VERSION ""

NS_ :

BS_:

BU_:

BO_ 608 V2I_Status: 8 Vector__XXX
 SG_ V2I_Status : 0|4@1+ (1,0) [0|255] "" Vector__XXX
 SG_ Real_Auto_On : 4|1@1+ (1,0) [0|1] "" Vector__XXX

BO_ 535 Gear_Status: 8 Vector__XXX
 SG_ Gear_Status : 0|8@1+ (1,0) [0|255] "" Vector__XXX

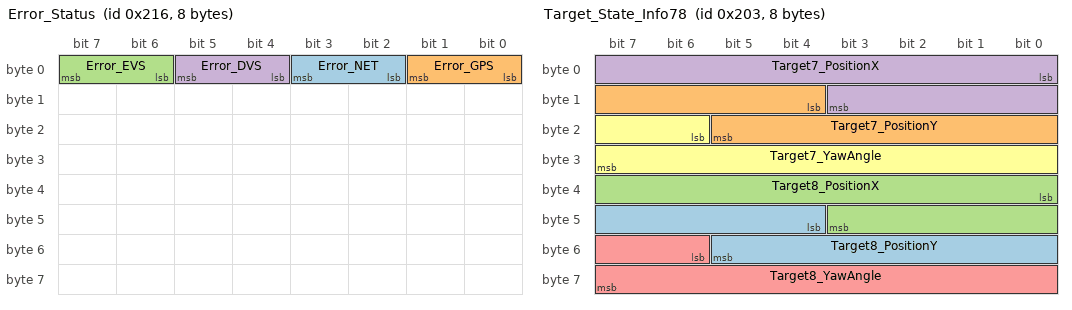
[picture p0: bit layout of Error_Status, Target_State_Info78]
BO_ 534 Error_Status: 8 Vector__XXX
 SG_ Error_NET : 2|2@1+ (1,0) [0|3] "" Vector__XXX
 SG_ Error_GPS : 0|2@1+ (1,0) [0|3] "" Vector__XXX
 SG_ Error_EVS : 6|2@1+ (1,0) [0|3] "" Vector__XXX
 SG_ Error_DVS : 4|2@1+ (1,0) [0|3] "" Vector__XXX

BO_ 515 Target_State_Info78: 8 Vector__XXX
 SG_ Target8_PositionY : 44|10@1- (0.05,0) [-25.6|25.55] "" Vector__XXX
 SG_ Target7_PositionY : 12|10@1- (0.05,0) [-25.6|25.55] "" Vector__XXX
 SG_ Target8_PositionX : 32|12@1- (0.05,0) [-102.4|102.35] "" Vector__XXX
 SG_ Target7_PositionX : 0|12@1- (0.05,0) [-102.4|102.35] "" Vector__XXX
 SG_ Target8_YawAngle : 54|10@1- (0.01,0) [-5.12|5.11] "" Vector__XXX
 SG_ Target7_YawAngle : 22|10@1- (0.01,0) [-5.12|5.11] "" Vector__XXX

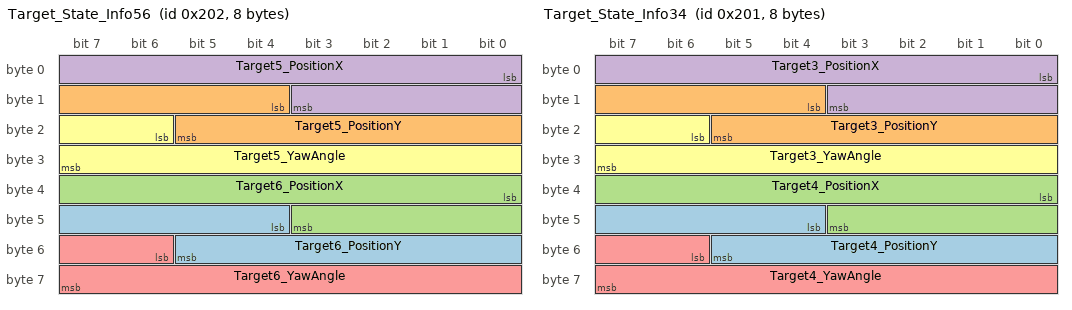
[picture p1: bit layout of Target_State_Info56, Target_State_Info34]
BO_ 514 Target_State_Info56: 8 Vector__XXX
 SG_ Target6_PositionY : 44|10@1- (0.05,0) [-25.6|25.55] "" Vector__XXX
 SG_ Target5_PositionY : 12|10@1- (0.05,0) [-25.6|25.55] "" Vector__XXX
 SG_ Target6_PositionX : 32|12@1- (0.05,0) [-102.4|102.35] "" Vector__XXX
 SG_ Target5_PositionX : 0|12@1- (0.05,0) [-102.4|102.35] "" Vector__XXX
 SG_ Target6_YawAngle : 54|10@1- (0.01,0) [-5.12|5.11] "" Vector__XXX
 SG_ Target5_YawAngle : 22|10@1- (0.01,0) [-5.12|5.11] "" Vector__XXX

BO_ 513 Target_State_Info34: 8 Vector__XXX
 SG_ Target4_PositionY : 44|10@1- (0.05,0) [-25.6|25.55] "" Vector__XXX
 SG_ Target3_PositionY : 12|10@1- (0.05,0) [-25.6|25.55] "" Vector__XXX
 SG_ Target4_PositionX : 32|12@1- (0.05,0) [-102.4|102.35] "" Vector__XXX
 SG_ Target3_PositionX : 0|12@1- (0.05,0) [-102.4|102.35] "" Vector__XXX
 SG_ Target4_YawAngle : 54|10@1- (0.01,0) [-5.12|5.11] "" Vector__XXX
 SG_ Target3_YawAngle : 22|10@1- (0.01,0) [-5.12|5.11] "" Vector__XXX

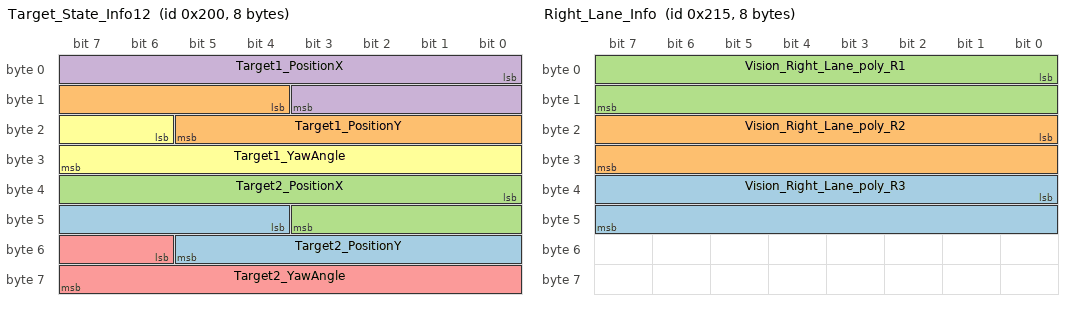
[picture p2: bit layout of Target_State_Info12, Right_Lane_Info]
BO_ 512 Target_State_Info12: 8 Vector__XXX
 SG_ Target2_PositionY : 44|10@1- (0.05,0) [-25.6|25.55] "" Vector__XXX
 SG_ Target1_PositionY : 12|10@1- (0.05,0) [-25.6|25.55] "" Vector__XXX
 SG_ Target2_PositionX : 32|12@1- (0.05,0) [-102.4|102.35] "" Vector__XXX
 SG_ Target1_PositionX : 0|12@1- (0.05,0) [-102.4|102.35] "" Vector__XXX
 SG_ Target2_YawAngle : 54|10@1- (0.01,0) [-5.12|5.11] "" Vector__XXX
 SG_ Target1_YawAngle : 22|10@1- (0.01,0) [-5.12|5.11] "" Vector__XXX

BO_ 533 Right_Lane_Info: 8 Vector__XXX
 SG_ Vision_Right_Lane_poly_R3 : 32|16@1- (0.05,0) [-1638.4|1638.35] "" Vector__XXX
 SG_ Vision_Right_Lane_poly_R2 : 16|16@1- (0.05,0) [-1638.4|1638.35] "" Vector__XXX
 SG_ Vision_Right_Lane_poly_R1 : 0|16@1- (0.05,0) [-1638.4|1638.35] "" Vector__XXX

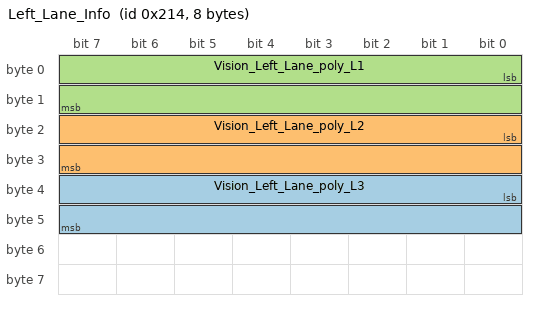
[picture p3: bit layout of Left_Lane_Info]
BO_ 532 Left_Lane_Info: 8 Vector__XXX
 SG_ Vision_Left_Lane_poly_L3 : 32|16@1- (0.05,0) [-1638.4|1638.35] "" Vector__XXX
 SG_ Vision_Left_Lane_poly_L2 : 16|16@1- (0.05,0) [-1638.4|1638.35] "" Vector__XXX
 SG_ Vision_Left_Lane_poly_L1 : 0|16@1- (0.05,0) [-1638.4|1638.35] "" Vector__XXX

BO_ 1287 Local_Trajectory_Info6: 8 Vector__XXX
 SG_ Local_poly_y5 : 0|32@1- (0.0001,0) [-100|100] "" Vector__XXX

BO_ 1284 Local_Trajectory_Info3: 8 Vector__XXX
 SG_ Local_poly_x5 : 0|32@1- (0.0001,0) [-100|100] "" Vector__XXX

BO_ 528 Ego_Speed: 8 Vector__XXX
 SG_ Speed_Ego : 0|16@1+ (1,0) [0|1000] "" Vector__XXX

BO_ 529 Global_Pose: 8 Vector__XXX
 SG_ PosLon : 32|32@1- (1E-006,0) [-180|180] "deg" Vector__XXX
 SG_ PosLat : 0|32@1- (1E-006,0) [-90|90] "deg" Vector__XXX

BA_DEF_ SG_  "GenSigSendType" ENUM  "Cyclic","OnWrite","OnWriteWithRepetition","OnChange","OnChangeWithRepetition","IfActive","IfActiveWithRepetition","NoSigSendType";
BA_DEF_ BO_  "GenMsgSendType" ENUM  "Cyclic","not_used","not_used","not_used","not_used","Cyclic","not_used","IfActive","NoMsgSendType";
BA_DEF_  "DBName" STRING ;
BA_DEF_  "BusType" STRING ;
BA_DEF_DEF_  "GenSigSendType" "Cyclic";
BA_DEF_DEF_  "GenMsgSendType" "NoMsgSendType";
BA_DEF_DEF_  "DBName" "";
BA_DEF_DEF_  "BusType" "CAN";
BA_ "DBName" "CAN_UI_TX_to_UI";
